# ATmega1281 device description
Architecture: AVR8; Family: megaAVR
Registers are 8-bit, access not given, no defined reset value unless marked. A register's access mark holds for its fields unless they carry their own. Offsets are from the block's base; [hi:lo] are bit positions; {n}, {i} and the like mark numbered series; 'fields as' and 'values as' point back to an identical list.

## ADC — Analog-to-Digital Converter
Instances: ADC 0x00
0x78 ADC 16-bit — ADC Data Register Bytes
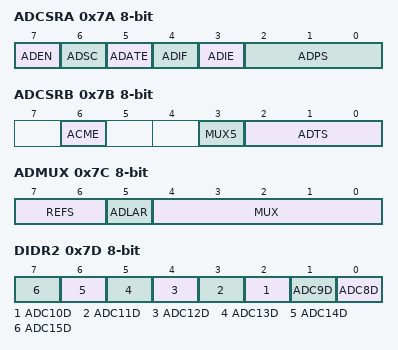
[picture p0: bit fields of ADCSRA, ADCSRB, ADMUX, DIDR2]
0x7A ADCSRA — The ADC Control and Status register A
  [7] ADEN — ADC Enable
  [6] ADSC — ADC Start Conversion
  [5] ADATE — ADC Auto Trigger Enable
  [4] ADIF — ADC Interrupt Flag
  [3] ADIE — ADC Interrupt Enable
  [2:0] ADPS — ADC Prescaler Select Bits
    0=2; 1=2; 2=4; 3=8; 4=16; 5=32; 6=64; 7=128
0x7B ADCSRB — The ADC Control and Status register B
  [6] ACME
  [3] MUX5 — Analog Channel and Gain Selection Bits
  [2:0] ADTS — ADC Auto Trigger Source bits
    0=Free Running mode; 1=Analog Comparator; 2=External Interrupt Request 0; 3=Timer/Counter0 Compare Match A; 4=Timer/Counter0 Overflow; 5=Timer/Counter1 Compare Match B; 6=Timer/Counter1 Overflow; 7=Timer/Counter1 Capture Event
0x7C ADMUX — The ADC multiplexer Selection Register
  [7:6] REFS — Reference Selection Bits
    0=AREF, Internal Vref turned off; 1=AVCC with external capacitor at AREF pin; 2=Internal 1.1V Voltage Reference with external capacitor at AREF pin; 3=Internal 2.56V Voltage Reference with external capacitor at AREF pin
  [5] ADLAR — Left Adjust Result
  [4:0] MUX — Analog Channel and Gain Selection Bits
    {v}=ADC{v} (ADC Single Ended Input pin {v}) (v=0..7); 8=ADC0_ADC0_10X (ADC Differential Inputs Postive pin 0 Negative pin 0 10x Gain); 9=ADC1_ADC0_10X (ADC Differential Inputs Postive pin 1 Negative pin 0 10x Gain); 10=ADC0_ADC0_200x (ADC Differential Inputs Postive pin 0 Negative pin 0 200x Gain); 11=ADC1_ADC0_200X (ADC Differential Inputs Postive pin 1 Negative pin 0 200x Gain); 12=ADC2_ADC2_10X (ADC Differential Inputs Postive pin 2 Negative pin 2 10x Gain); 13=ADC3_ADC2_10X (ADC Differential Inputs Postive pin 3 Negative pin 2 10x Gain); 14=ADC2_ADC2_200X (ADC Differential Inputs Postive pin 2 Negative pin 2 200x Gain); 15=ADC3_ADC2_200X (ADC Differential Inputs Postive pin 3 Negative pin 2 200x Gain); {v}=ADC{v-16}_ADC1_1X (ADC Differential Inputs Postive pin {v-16} Negative pin 1 1x Gain) (v=16..23); {v}=ADC{v-24}_ADC2_1X (ADC Differential Inputs Postive pin {v-24} Negative pin 2 1x Gain) (v=24..29); 30=ADC_VBG (Internal Reference (VBG)); 31=ADC_GND (0V (GND)); {v}=ADC{v-24} (ADC Single Ended Input pin {v-24}) (v=32..39); 40=ADC8_ADC8_10X (ADC Differential Inputs Postive pin 8 Negative pin 8 10x Gain); 41=ADC9_ADC8_10X (ADC Differential Inputs Postive pin 9 Negative pin 8 10x Gain); 42=ADC8_ADC8_200x (ADC Differential Inputs Postive pin 8 Negative pin 8 200x Gain); 43=ADC9_ADC8_200X (ADC Differential Inputs Postive pin 9 Negative pin 8 200x Gain); 44=ADC10_ADC10_10X (ADC Differential Inputs Postive pin 10 Negative pin 10 10x Gain); 45=ADC11_ADC10_10X (ADC Differential Inputs Postive pin 11 Negative pin 10 10x Gain); 46=ADC10_ADC10_200X (ADC Differential Inputs Postive pin 10 Negative pin 10 200x Gain); 47=ADC11_ADC10_200X (ADC Differential Inputs Postive pin 11 Negative pin 10 200x Gain); {v}=ADC{v-40}_ADC9_1X (ADC Differential Inputs Postive pin {v-40} Negative pin 9 1x Gain) (v=48..55); {v}=ADC{v-48}_ADC10_1X (ADC Differential Inputs Postive pin {v-48} Negative pin 10 1x Gain) (v=56..61)
0x7D DIDR2 — Digital Input Disable Register
  [n-8] ADC{n}D (n=8..15)
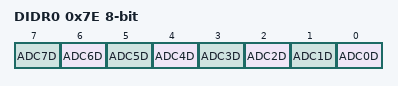
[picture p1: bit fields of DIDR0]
0x7E DIDR0 — Digital Input Disable Register
  [n] ADC{n}D (n=0..7)

## BOOT_LOAD — Bootloader
Instances: BOOT_LOAD 0x00
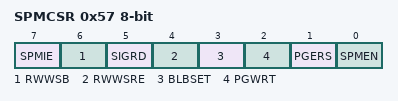
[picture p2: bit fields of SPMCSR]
0x57 SPMCSR — Store Program Memory Control Register
  [7] SPMIE — SPM Interrupt Enable
  [6] RWWSB — Read While Write Section Busy
  [5] SIGRD — Signature Row Read
  [4] RWWSRE — Read While Write section read enable
  [3] BLBSET — Boot Lock Bit Set
  [2] PGWRT — Page Write
  [1] PGERS — Page Erase
  [0] SPMEN — Store Program Memory Enable

## CPU — CPU Registers
Instances: CPU 0x00
Parameters: CORE_VERSION=V3
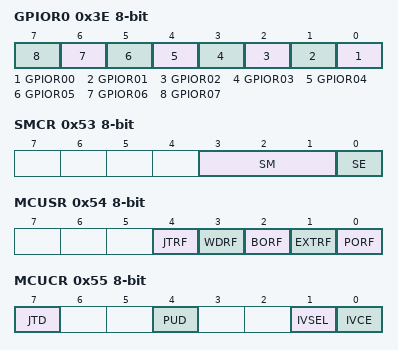
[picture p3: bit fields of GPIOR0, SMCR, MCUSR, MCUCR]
0x3E GPIOR0 — General Purpose IO Register 0
  [n] GPIOR{n:02} (n=0..7) — General Purpose IO Register 0 bit {n}
0x4A GPIOR1 — General Purpose IO Register 1
  [7:0] GPIOR (bit 10 of the value upward) — General Purpose IO Register 1 bis
0x4B GPIOR2 — General Purpose IO Register 2
  [7:0] GPIOR (bit 20 of the value upward) — General Purpose IO Register 2 bis
0x53 SMCR — Sleep Mode Control Register
  [3:1] SM — Sleep Mode Select bits
    0=IDLE; 1=ADC (ADC Noise Reduction (If Available)); 2=PDOWN (Power Down); 3=PSAVE (Power Save); 6=STDBY (Standby); 7=ESTDBY (Extended Standby)
  [0] SE — Sleep Enable
0x54 MCUSR — MCU Status Register
  [4] JTRF — JTAG Reset Flag
  [3] WDRF — Watchdog Reset Flag
  [2] BORF — Brown-out Reset Flag
  [1] EXTRF — External Reset Flag
  [0] PORF — Power-on reset flag
0x55 MCUCR — MCU Control Register
  [7] JTD — JTAG Interface Disable
  [4] PUD — Pull-up disable
  [1] IVSEL — Interrupt Vector Select
  [0] IVCE — Interrupt Vector Change Enable
0x5B RAMPZ bits used 1:0 — RAM Page Z Select Register
0x5D SP 16-bit — Stack Pointer
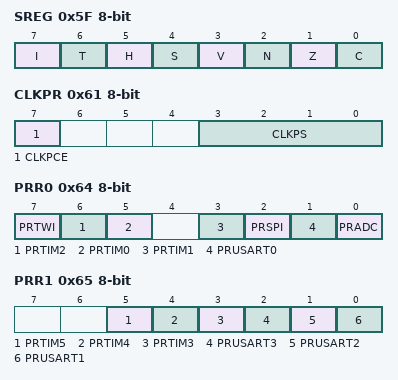
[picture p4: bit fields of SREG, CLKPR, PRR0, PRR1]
0x5F SREG — Status Register
  [7] I — Global Interrupt Enable
  [6] T — Bit Copy Storage
  [5] H — Half Carry Flag
  [4] S — Sign Bit
  [3] V — Two's Complement Overflow Flag
  [2] N — Negative Flag
  [1] Z — Zero Flag
  [0] C — Carry Flag
0x61 CLKPR
  [7] CLKPCE
  [3:0] CLKPS
    0=1; 1=2; 2=4; 3=8; 4=16; 5=32; 6=64; 7=128; 8=256
0x64 PRR0 — Power Reduction Register0
  [7] PRTWI — Power Reduction TWI
  [6] PRTIM2 — Power Reduction Timer/Counter2
  [5] PRTIM0 — Power Reduction Timer/Counter0
  [3] PRTIM1 — Power Reduction Timer/Counter1
  [2] PRSPI — Power Reduction Serial Peripheral Interface
  [1] PRUSART0 — Power Reduction USART0
  [0] PRADC — Power Reduction ADC
0x65 PRR1 — Power Reduction Register1
  [5] PRTIM5 — Power Reduction Timer/Counter5
  [4] PRTIM4 — Power Reduction Timer/Counter4
  [3] PRTIM3 — Power Reduction Timer/Counter3
  [2] PRUSART3 — Power Reduction USART3
  [1] PRUSART2 — Power Reduction USART2
  [0] PRUSART1 — Power Reduction USART1
0x66 OSCCAL — Oscillator Calibration Value
  [7:0] OSCCAL — Oscillator Calibration
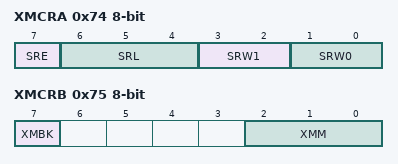
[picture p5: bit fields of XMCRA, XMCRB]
0x74 XMCRA — External Memory Control Register A
  [7] SRE — External SRAM Enable
  [6:4] SRL — Wait state page limit
    0=LS = N/A, US = 0x1100 - 0xFFFF; 1=LS = 0x2200 - 0x1FFF, US = 0x2000 - 0xFFFF; 2=LS = 0x2200 - 0x3FFF, US = 0x4000 - 0xFFFF; 3=LS = 0x2200 - 0x5FFF, US = 0x6000 - 0xFFFF; 4=LS = 0x2200 - 0x7FFF, US = 0x8000 - 0xFFFF; 5=LS = 0x2200 - 0x9FFF, US = 0xA000 - 0xFFFF; 6=LS = 0x2200 - 0xBFFF, US = 0xC000 - 0xFFFF; 7=LS = 0x2200 - 0xDFFF, US = 0xE000 - 0xFFFF
  [3:2] SRW1 — Wait state select bit upper page
    0=No wait-states; 1=Wait one cycle during read/write strobe; 2=Wait two cycles during read/write strobe; 3=Wait two cycles during read/write and wait one cycle before driving out new address
  [1:0] SRW0 — Wait state select bit lower page
    values as SRW1
0x75 XMCRB — External Memory Control Register B
  [7] XMBK — External Memory Bus Keeper Enable
  [2:0] XMM — External Memory High Mask
    0=None; 1=Px7; 2=Px7-Px6; 3=Px7-Px5; 4=Px7-Px4; 5=Px7-Px3; 6=Px7-Px2; 7=Full Port X
Value list OSCCAL_VALUE_ADDRESSES: 0=8_0_MHz
